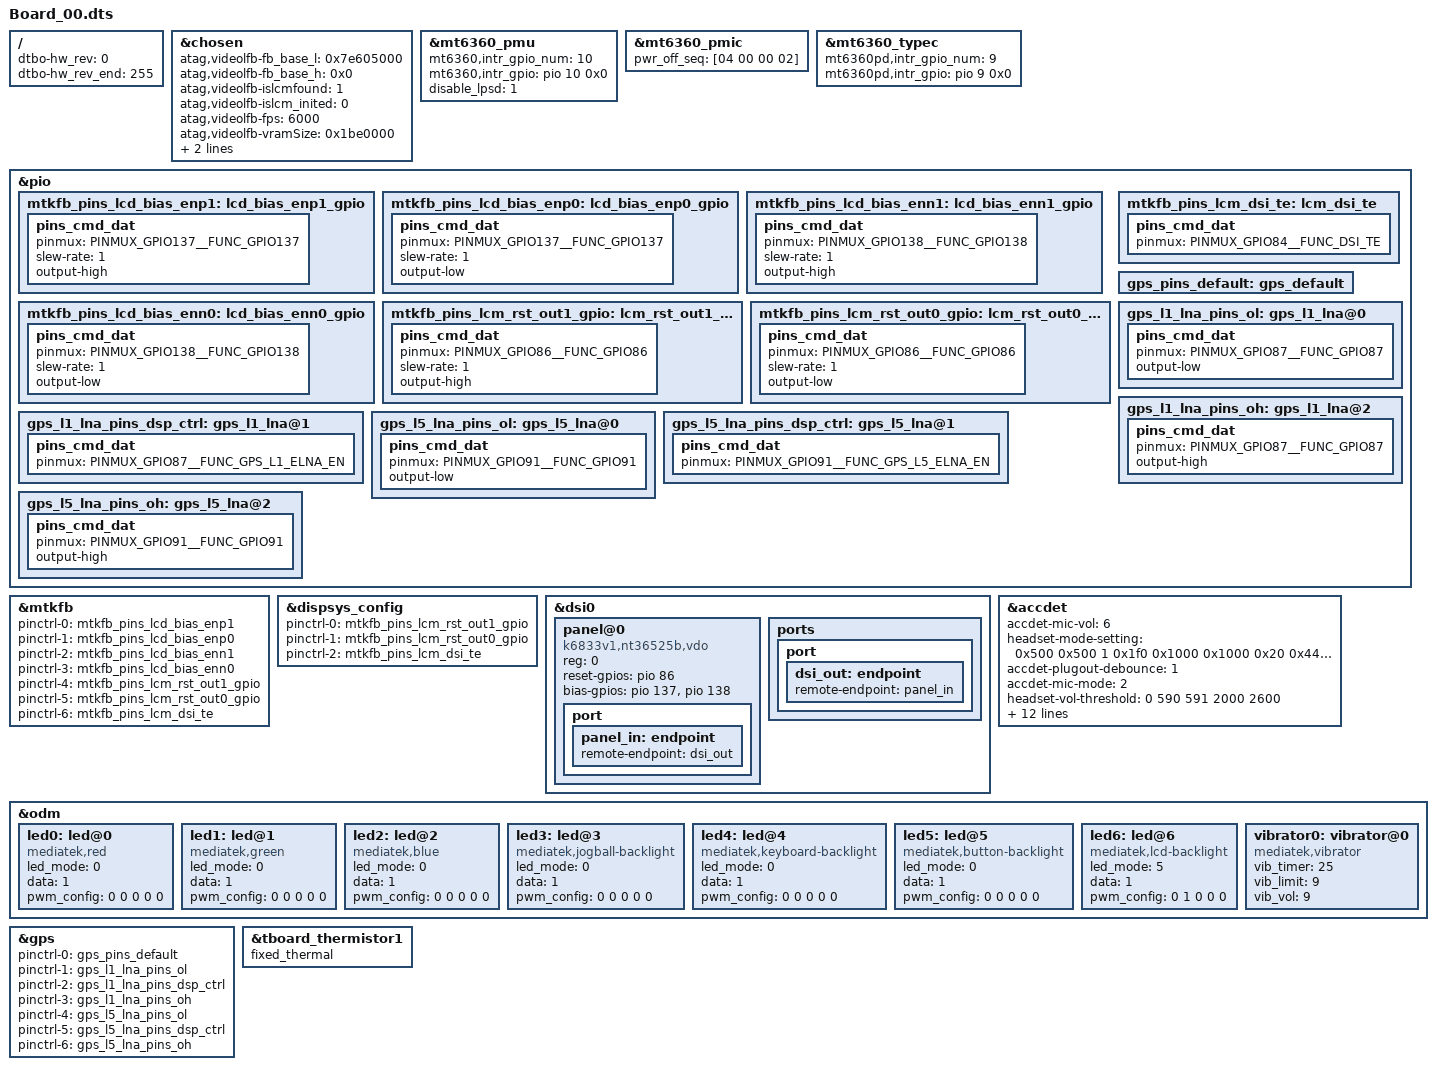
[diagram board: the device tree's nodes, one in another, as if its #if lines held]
/*
 * Mediatek's mt6833 SoC device tree source
 *
 * Copyright (C) 2021 MediaTek Inc.
 *
 * This program is free software; you can redistribute it and/or modify
 * it under the terms of the GNU General Public License version 2 as
 * published by the Free Software Foundation.
 *
 * This program is distributed in the hope that it will be useful,
 * but WITHOUT ANY WARRANTY; without even the implied warranty of
 * MERCHANTABILITY or FITNESS FOR A PARTICULAR PURPOSE.
 * See http://www.gnu.org/licenses/gpl-2.0.html for more details.
 */

#include <dt-bindings/interrupt-controller/irq.h>
#include <dt-bindings/interrupt-controller/arm-gic.h>
#ifndef CONFIG_FPGA_EARLY_PORTING
#include <dt-bindings/pinctrl/mt6833-pinfunc.h>
#endif
#include <generated/autoconf.h>

/ {
	fragment@model {
		target-path = "/";
		__overlay__ {
			dtbo-hw_rev = <0>;
			dtbo-hw_rev_end = <255>;
		};
	};
};

/* chosen */
&chosen {
	atag,videolfb-fb_base_l = <0x7e605000>;
	atag,videolfb-fb_base_h = <0x0>;
	atag,videolfb-islcmfound = <1>;
	atag,videolfb-islcm_inited = <0>;
	atag,videolfb-fps= <6000>;
	atag,videolfb-vramSize= <0x1be0000>;
	atag,videolfb-lcmname=
		"nt35595_fhd_dsi_cmd_truly_nt50358_drv";
};

#if ! defined(CONFIG_BATTERY_SAMSUNG)
#if (CONFIG_MTK_GAUGE_VERSION == 30)
#include "mediatek/bat_setting/k6833v1_64_titan_highland/battery_prop.dtsi"
#endif
#endif

&mt6360_pmu {
	mt6360,intr_gpio_num = <10>; /* direct defined GPIO num */
	mt6360,intr_gpio = <&pio 10 0x0>;
	disable_lpsd = <1>;
};

&mt6360_pmic {
	pwr_off_seq = [04 00 00 02];
};

&mt6360_typec {
	mt6360pd,intr_gpio_num = <9>; /* direct defined GPIO num */
	mt6360pd,intr_gpio = <&pio 9 0x0>;
};

#ifndef CONFIG_FPGA_EARLY_PORTING
&pio {
	mtkfb_pins_lcd_bias_enp1: lcd_bias_enp1_gpio {
		pins_cmd_dat {
			pinmux = <PINMUX_GPIO137__FUNC_GPIO137>;
			slew-rate = <1>;
			output-high;
		};
	};

	mtkfb_pins_lcd_bias_enp0: lcd_bias_enp0_gpio {
		pins_cmd_dat {
			pinmux = <PINMUX_GPIO137__FUNC_GPIO137>;
			slew-rate = <1>;
			output-low;
		};
	};

	mtkfb_pins_lcd_bias_enn1: lcd_bias_enn1_gpio {
		pins_cmd_dat {
			pinmux = <PINMUX_GPIO138__FUNC_GPIO138>;
			slew-rate = <1>;
			output-high;
		};
	};

	mtkfb_pins_lcd_bias_enn0: lcd_bias_enn0_gpio {
		pins_cmd_dat {
			pinmux = <PINMUX_GPIO138__FUNC_GPIO138>;
			slew-rate = <1>;
			output-low;
		};
	};

	mtkfb_pins_lcm_rst_out1_gpio: lcm_rst_out1_gpio {
		pins_cmd_dat {
			pinmux = <PINMUX_GPIO86__FUNC_GPIO86>;
			slew-rate = <1>;
			output-high;
		};
	};

	mtkfb_pins_lcm_rst_out0_gpio: lcm_rst_out0_gpio {
		pins_cmd_dat {
			pinmux = <PINMUX_GPIO86__FUNC_GPIO86>;
			slew-rate = <1>;
			output-low;
		};
	};
	mtkfb_pins_lcm_dsi_te: lcm_dsi_te {
		pins_cmd_dat {
			pinmux = <PINMUX_GPIO84__FUNC_DSI_TE>;
		};
	};
};

&mtkfb {
	pinctrl-names = "lcd_bias_enp1_gpio", "lcd_bias_enp0_gpio",
		"lcd_bias_enn1_gpio", "lcd_bias_enn0_gpio",
		"lcm_rst_out1_gpio", "lcm_rst_out0_gpio",
		"mode_te_te";
	pinctrl-0 = <&mtkfb_pins_lcd_bias_enp1>;
	pinctrl-1 = <&mtkfb_pins_lcd_bias_enp0>;
	pinctrl-2 = <&mtkfb_pins_lcd_bias_enn1>;
	pinctrl-3 = <&mtkfb_pins_lcd_bias_enn0>;
	pinctrl-4 = <&mtkfb_pins_lcm_rst_out1_gpio>;
	pinctrl-5 = <&mtkfb_pins_lcm_rst_out0_gpio>;
	pinctrl-6 = <&mtkfb_pins_lcm_dsi_te>;
	status = "okay";
};
&dispsys_config {
	pinctrl-names =
		"lcm_rst_out1_gpio", "lcm_rst_out0_gpio",
		"mode_te_te";
	pinctrl-0 = <&mtkfb_pins_lcm_rst_out1_gpio>;
	pinctrl-1 = <&mtkfb_pins_lcm_rst_out0_gpio>;
	pinctrl-2 = <&mtkfb_pins_lcm_dsi_te>;
	status = "okay";
};

&dsi0 {
	status = "okay";
	#address-cells = <1>;
	#size-cells = <0>;
	panel@0 {
		compatible = "k6833v1,nt36525b,vdo";
		reg = <0>;
		reset-gpios = <&pio 86 0>;
		bias-gpios = <&pio 137 0>,
			<&pio 138 0>;
		pinctrl-names = "default";
		port {
			panel_in: endpoint {
				remote-endpoint = <&dsi_out>;
			};
		};
	};
	ports {
		port {
			dsi_out: endpoint {
				remote-endpoint = <&panel_in>;
			};
		};
	};
};
#endif

/* accdet start */
&accdet {
	/* accdet micbias voltage: 0x09:2.85v 0x08:2.8v 0x07,
	 * 2.7v;0x05,2.5v;0x02,1.9v
	 */
	accdet-mic-vol = <6>;
	/* accdet pwm_width, pwm_thresh, fall_delay, rise_delay
	 * debounce0, debounce1, debounce3, debounce4
	 * eint pwm_width, eint pwm_thresh
	 * eint deb(debounce0, debounce1, debounce2, debounce3), inv_debounce
	 */
	headset-mode-setting = <0x500 0x500 1 0x1f0
				0x1000 0x1000 0x20 0x44
				0x4 0x1
				0xe 0x3 0x3 0x5 0xe>;
	accdet-plugout-debounce = <1>;
	/*1:ACC mode, 2:low cost without in bias, 6:low cost with in bias*/
	accdet-mic-mode = <2>;
	/*min_3pole--max_3pole--min_4pole--max_4pole--vol_bias*/
	headset-vol-threshold = <0 590 591 2000 2600>;
	/*0--MD_MAX--UP_MAX--DW_MAX*/
	headset-three-key-threshold = <0 80 220 400>;
	headset-three-key-threshold-CDD = <0 121 192 600>;
	/*0--MD_MAX--VOICE_MAX--UP_MAX--DW_MAX*/
	headset-four-key-threshold = <0 83 115 189 400>;

	moisture_detect_enable = <1>;
	moisture_detect_mode = <1>;
	eint_detect_mode = <1>;
	/* use external resitance */
	eint_use_ext_res = <1>;
	/* select VTH to 2v, 0:2.8V,1:2.4V,2:2V */
	eint_comp_vth = <2>;

	/* moisture SW mode config start, use external resister or not.
	 */
	moisture-ver = <1>;
	moisture_use_ext_res = <1>;
	/* moisture of water resister ohm, SW mode by auxadc*/
	moisture-water-r = <50000>;
	moisture-vm = <100>;
	/* moisture SW mode config end */

	status = "okay";
};
/* accdet end */

&odm {
	led0:led@0 {
		compatible = "mediatek,red";
		led_mode = <0>;
		data = <1>;
		pwm_config = <0 0 0 0 0>;
	};
	led1:led@1 {
		compatible = "mediatek,green";
		led_mode = <0>;
		data = <1>;
		pwm_config = <0 0 0 0 0>;
	};
	led2:led@2 {
		compatible = "mediatek,blue";
		led_mode = <0>;
		data = <1>;
		pwm_config = <0 0 0 0 0>;
	};
	led3:led@3 {
		compatible = "mediatek,jogball-backlight";
		led_mode = <0>;
		data = <1>;
		pwm_config = <0 0 0 0 0>;
	};
	led4:led@4 {
		compatible = "mediatek,keyboard-backlight";
		led_mode = <0>;
		data = <1>;
		pwm_config = <0 0 0 0 0>;
	};
	led5:led@5 {
		compatible = "mediatek,button-backlight";
		led_mode = <0>;
		data = <1>;
		pwm_config = <0 0 0 0 0>;
	};
	led6:led@6 {
		compatible = "mediatek,lcd-backlight";
		led_mode = <5>;
		data = <1>;
		pwm_config = <0 1 0 0 0>;
	};
	vibrator0:vibrator@0 {
		compatible = "mediatek,vibrator";
		vib_timer = <25>;
		vib_limit = <9>;
		vib_vol= <9>;
	};
};
/* GPS GPIO standardization start */
&pio {
	gps_pins_default: gps_default {
	};

	gps_l1_lna_pins_ol: gps_l1_lna@0 {
		pins_cmd_dat {
			pinmux = <PINMUX_GPIO87__FUNC_GPIO87>;
			output-low;
		};
	};
	gps_l1_lna_pins_dsp_ctrl: gps_l1_lna@1 {
		pins_cmd_dat {
			pinmux = <PINMUX_GPIO87__FUNC_GPS_L1_ELNA_EN>;
		};
	};
	gps_l1_lna_pins_oh: gps_l1_lna@2 {
		pins_cmd_dat {
			pinmux = <PINMUX_GPIO87__FUNC_GPIO87>;
			output-high;
		};
	};

	gps_l5_lna_pins_ol: gps_l5_lna@0 {
		pins_cmd_dat {
			pinmux = <PINMUX_GPIO91__FUNC_GPIO91>;
			output-low;
		};
	};
	gps_l5_lna_pins_dsp_ctrl: gps_l5_lna@1 {
		pins_cmd_dat {
			pinmux = <PINMUX_GPIO91__FUNC_GPS_L5_ELNA_EN>;
		};
	};
	gps_l5_lna_pins_oh: gps_l5_lna@2 {
		pins_cmd_dat {
			pinmux = <PINMUX_GPIO91__FUNC_GPIO91>;
			output-high;
		};
	};
};

&gps {
	pinctrl-names = "default",
		"gps_l1_lna_disable",
		"gps_l1_lna_dsp_ctrl",
		"gps_l1_lna_enable",
		"gps_l5_lna_disable",
		"gps_l5_lna_dsp_ctrl",
		"gps_l5_lna_enable";
	pinctrl-0 = <&gps_pins_default>;
	pinctrl-1 = <&gps_l1_lna_pins_ol>;
	pinctrl-2 = <&gps_l1_lna_pins_dsp_ctrl>;
	pinctrl-3 = <&gps_l1_lna_pins_oh>;
	pinctrl-4 = <&gps_l5_lna_pins_ol>;
	pinctrl-5 = <&gps_l5_lna_pins_dsp_ctrl>;
	pinctrl-6 = <&gps_l5_lna_pins_oh>;
	status = "okay";
};
/* GPS GPIO standardization end */

&tboard_thermistor1 {
	fixed_thermal;
};

/*End of this file, DO NOT ADD ANYTHING HERE*/
